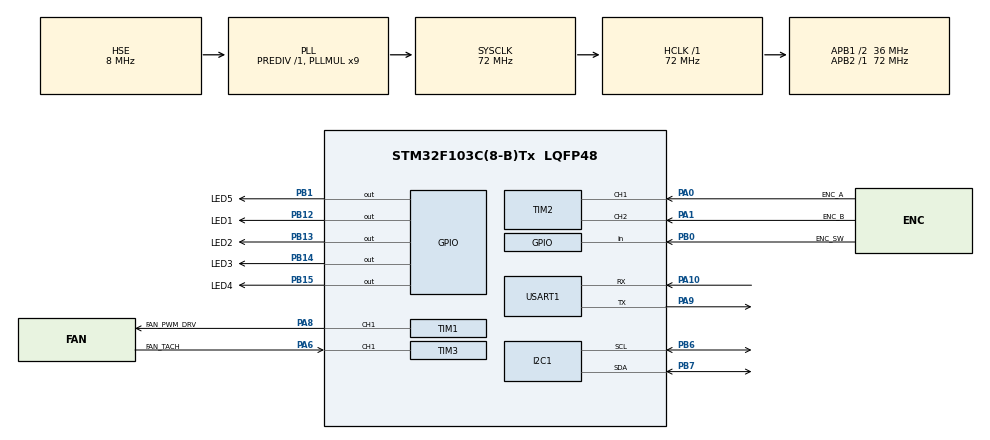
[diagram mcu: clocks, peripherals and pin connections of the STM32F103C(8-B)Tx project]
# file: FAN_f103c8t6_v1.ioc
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FREERTOS.Tasks01=defaultTask,24,128,StartDefaultTask,Default,NULL,Dynamic,NULL,NULL;myTask02,11,256,StartTask02,Default,NULL,Dynamic,NULL,NULL;myTask03,11,256,StartTask03,Default,NULL,Dynamic,NULL,NULL
FREERTOS.configTOTAL_HEAP_SIZE=8192
Mcu.Family=STM32F1
Mcu.Name=STM32F103C(8-B)Tx
Mcu.Package=LQFP48
NVIC.I2C1_ER_IRQn=true\:5\:0\:false\:false\:true\:true\:true\:true\:true
NVIC.I2C1_EV_IRQn=true\:5\:0\:false\:false\:true\:true\:true\:true\:true
NVIC.PriorityGroup=NVIC_PRIORITYGROUP_4
NVIC.TIM2_IRQn=true\:5\:0\:false\:false\:true\:true\:true\:true\:true
NVIC.TIM3_IRQn=true\:5\:0\:false\:false\:true\:true\:true\:true\:true
NVIC.TIM4_IRQn=true\:15\:0\:false\:false\:true\:false\:false\:true\:true
NVIC.TimeBase=TIM4_IRQn
NVIC.TimeBaseIP=TIM4
NVIC.USART1_IRQn=true\:5\:0\:false\:false\:true\:true\:true\:true\:true
PA0-WKUP.GPIO_Label=ENC_A
PA0-WKUP.Signal=S_TIM2_CH1_ETR
PA1.GPIO_Label=ENC_B
PA1.Signal=S_TIM2_CH2
PA10.Mode=Asynchronous
PA10.Signal=USART1_RX
PA13.Mode=JTAG_5_pins
PA13.Signal=SYS_JTMS-SWDIO
PA14.Mode=JTAG_5_pins
PA14.Signal=SYS_JTCK-SWCLK
PA15.Mode=JTAG_5_pins
PA15.Signal=SYS_JTDI
PA6.GPIO_Label=FAN_TACH
PA6.Signal=S_TIM3_CH1
PA8.GPIO_Label=FAN_PWM_DRV
PA8.Signal=S_TIM1_CH1
PA9.Mode=Asynchronous
PA9.Signal=USART1_TX
PB0.GPIO_Label=ENC_SW
PB0.Signal=GPIO_Input
PB1.GPIO_Label=LED5
PB1.PinState=GPIO_PIN_SET
PB1.Signal=GPIO_Output
PB12.GPIO_Label=LED1
PB12.PinState=GPIO_PIN_SET
PB12.Signal=GPIO_Output
PB13.GPIO_Label=LED2
PB13.PinState=GPIO_PIN_SET
PB13.Signal=GPIO_Output
PB14.GPIO_Label=LED3
PB14.PinState=GPIO_PIN_SET
PB14.Signal=GPIO_Output
PB15.GPIO_Label=LED4
PB15.PinState=GPIO_PIN_SET
PB15.Signal=GPIO_Output
PB3.Mode=JTAG_5_pins
PB3.Signal=SYS_JTDO-TRACESWO
PB4.Mode=JTAG_5_pins
PB4.Signal=SYS_NJTRST
PB6.Mode=I2C
PB6.Signal=I2C1_SCL
PB7.Mode=I2C
PB7.Signal=I2C1_SDA
PD0-OSC_IN.Mode=HSE-External-Oscillator
PD0-OSC_IN.Signal=RCC_OSC_IN
PD1-OSC_OUT.Mode=HSE-External-Oscillator
PD1-OSC_OUT.Signal=RCC_OSC_OUT
ProjectManager.HeapSize=0x200
ProjectManager.StackSize=0x400
ProjectManager.TargetToolchain=MDK-ARM V5.32
RCC.AHBFreq_Value=72000000
RCC.APB1CLKDivider=RCC_HCLK_DIV2
RCC.APB1Freq_Value=36000000
RCC.APB1TimFreq_Value=72000000
RCC.APB2Freq_Value=72000000
RCC.APB2TimFreq_Value=72000000
RCC.HCLKFreq_Value=72000000
RCC.PLLMUL=RCC_PLL_MUL9
RCC.PLLSourceVirtual=RCC_PLLSOURCE_HSE
RCC.SYSCLKFreq_VALUE=72000000
RCC.SYSCLKSource=RCC_SYSCLKSOURCE_PLLCLK
RCC.USBFreq_Value=72000000
SH.S_TIM1_CH1.0=TIM1_CH1,PWM Generation1 CH1
SH.S_TIM2_CH1_ETR.0=TIM2_CH1,Encoder_Interface
SH.S_TIM2_CH2.0=TIM2_CH2,Encoder_Interface
SH.S_TIM3_CH1.0=TIM3_CH1,Input_Capture1_from_TI1
TIM1.Channel-PWM\ Generation1\ CH1=TIM_CHANNEL_1
TIM1.Period=2879
TIM2.EncoderMode=TIM_ENCODERMODE_TI12
TIM2.IC1Filter=15
TIM2.IC2Filter=15
TIM3.Channel-Input_Capture1_from_TI1=TIM_CHANNEL_1
TIM3.ICFilter_CH1=8
TIM3.ICPolarity_CH1=TIM_INPUTCHANNELPOLARITY_FALLING
TIM3.Period=65535
TIM3.Prescaler=7199
USART1.VirtualMode=VM_ASYNC
VP_FREERTOS_VS_CMSIS_V2.Mode=CMSIS_V2
VP_SYS_VS_tim4.Mode=TIM4
VP_TIM1_VS_ClockSourceINT.Mode=Internal
VP_TIM3_VS_ClockSourceINT.Mode=Internal
board=custom

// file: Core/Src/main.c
/* USER CODE BEGIN Header */
/**
  ******************************************************************************
  * @file           : main.c
  * @brief          : Main program body
  ******************************************************************************
  * @attention
  *
  * Copyright (c) 2026 STMicroelectronics.
  * All rights reserved.
  *
  * This software is licensed under terms that can be found in the LICENSE file
  * in the root directory of this software component.
  * If no LICENSE file comes with this software, it is provided AS-IS.
  *
  ******************************************************************************
  */
/* USER CODE END Header */
#include "main.h"
#include "cmsis_os.h"
#include "i2c.h"
#include "tim.h"
#include "usart.h"
#include "gpio.h"

void SystemClock_Config(void);
void MX_FREERTOS_Init(void);

int main(void)
{

  /* MCU Configuration--------------------------------------------------------*/

  /* Reset of all peripherals, Initializes the Flash interface and the Systick. */
  HAL_Init();

  /* Configure the system clock */
  SystemClock_Config();

  /* Initialize all configured peripherals */
  MX_GPIO_Init();
  MX_I2C1_Init();
  MX_TIM1_Init();
  MX_TIM2_Init();
  MX_TIM3_Init();
  MX_USART1_UART_Init();

  /* Init scheduler */
  osKernelInitialize();  /* Call init function for freertos objects (in cmsis_os2.c) */
  MX_FREERTOS_Init();

  /* Start scheduler */
  osKernelStart();

  /* We should never get here as control is now taken by the scheduler */

  /* Infinite loop */
  while (1)
  {

  }
}

void SystemClock_Config(void)
{
  RCC_OscInitTypeDef RCC_OscInitStruct = {0};
  RCC_ClkInitTypeDef RCC_ClkInitStruct = {0};

  /** Initializes the RCC Oscillators according to the specified parameters
  * in the RCC_OscInitTypeDef structure.
  */
  RCC_OscInitStruct.OscillatorType = RCC_OSCILLATORTYPE_HSE;
  RCC_OscInitStruct.HSEState = RCC_HSE_ON;
  RCC_OscInitStruct.HSEPredivValue = RCC_HSE_PREDIV_DIV1;
  RCC_OscInitStruct.HSIState = RCC_HSI_ON;
  RCC_OscInitStruct.PLL.PLLState = RCC_PLL_ON;
  RCC_OscInitStruct.PLL.PLLSource = RCC_PLLSOURCE_HSE;
  RCC_OscInitStruct.PLL.PLLMUL = RCC_PLL_MUL9;
  if (HAL_RCC_OscConfig(&RCC_OscInitStruct) != HAL_OK)
  {
    Error_Handler();
  }

  /** Initializes the CPU, AHB and APB buses clocks
  */
  RCC_ClkInitStruct.ClockType = RCC_CLOCKTYPE_HCLK|RCC_CLOCKTYPE_SYSCLK
                              |RCC_CLOCKTYPE_PCLK1|RCC_CLOCKTYPE_PCLK2;
  RCC_ClkInitStruct.SYSCLKSource = RCC_SYSCLKSOURCE_PLLCLK;
  RCC_ClkInitStruct.AHBCLKDivider = RCC_SYSCLK_DIV1;
  RCC_ClkInitStruct.APB1CLKDivider = RCC_HCLK_DIV2;
  RCC_ClkInitStruct.APB2CLKDivider = RCC_HCLK_DIV1;

  if (HAL_RCC_ClockConfig(&RCC_ClkInitStruct, FLASH_LATENCY_2) != HAL_OK)
  {
    Error_Handler();
  }
}

void HAL_TIM_PeriodElapsedCallback(TIM_HandleTypeDef *htim)
{
  if (htim->Instance == TIM4)
  {
    HAL_IncTick();
  }
}

void Error_Handler(void)
{
  __disable_irq();
  while (1)
  {
  }
}

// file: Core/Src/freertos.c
/* USER CODE BEGIN Header */
/**
  ******************************************************************************
  * File Name          : freertos.c
  * Description        : Code for freertos applications
  ******************************************************************************
  * @attention
  *
  * Copyright (c) 2026 STMicroelectronics.
  * All rights reserved.
  *
  * This software is licensed under terms that can be found in the LICENSE file
  * in the root directory of this software component.
  * If no LICENSE file comes with this software, it is provided AS-IS.
  *
  ******************************************************************************
  */
/* USER CODE END Header */

#include "FreeRTOS.h"
#include "task.h"
#include "main.h"
#include "cmsis_os.h"

/* USER CODE BEGIN Includes */

/* 引入用户自有的 Task1、Task2、Task3 业务入口声明。 */
#include "user_work.h"

/* USER CODE END Includes */

/* Definitions for defaultTask */
osThreadId_t defaultTaskHandle;
const osThreadAttr_t defaultTask_attributes = {
  .name = "defaultTask",
  .stack_size = 128 * 4,
  .priority = (osPriority_t) osPriorityNormal,
};
/* Definitions for myTask02 */
osThreadId_t myTask02Handle;
const osThreadAttr_t myTask02_attributes = {
  .name = "myTask02",
  .stack_size = 256 * 4,
  .priority = (osPriority_t) osPriorityLow3,
};
/* Definitions for myTask03 */
osThreadId_t myTask03Handle;
const osThreadAttr_t myTask03_attributes = {
  .name = "myTask03",
  .stack_size = 256 * 4,
  .priority = (osPriority_t) osPriorityLow3,
};

void StartDefaultTask(void *argument);
void StartTask02(void *argument);
void StartTask03(void *argument);

void MX_FREERTOS_Init(void); /* (MISRA C 2004 rule 8.1) */

void MX_FREERTOS_Init(void) {

  /* Create the thread(s) */
  /* creation of defaultTask */
  defaultTaskHandle = osThreadNew(StartDefaultTask, NULL, &defaultTask_attributes);

  /* creation of myTask02 */
  myTask02Handle = osThreadNew(StartTask02, NULL, &myTask02_attributes);

  /* creation of myTask03 */
  myTask03Handle = osThreadNew(StartTask03, NULL, &myTask03_attributes);

}

void StartDefaultTask(void *argument)
{
  /* USER CODE BEGIN StartDefaultTask */
  /* 保留 CubeMX 任务入口；Task1 的业务循环和等待由自有模块管理。 */
  for(;;)
  {
    /* 调用用户封装的 Task1 常驻任务，后续业务在 user_work.c 中维护。 */
    My_Task1();
  }
  /* USER CODE END StartDefaultTask */
}

void StartTask02(void *argument)
{
  /* USER CODE BEGIN StartTask02 */
  /* 保留 CubeMX 任务入口；Task2 的业务循环和等待由自有模块管理。 */
  for(;;)
  {
    /* 调用用户封装的 Task2 常驻任务，后续业务在 user_work.c 中维护。 */
    My_Task2();
  }
  /* USER CODE END StartTask02 */
}

void StartTask03(void *argument)
{
  /* USER CODE BEGIN StartTask03 */
  /* 保留 CubeMX 任务入口；Task3 的业务循环和等待由自有模块管理。 */
  for(;;)
  {
    /* 调用用户封装的 Task3 常驻任务，后续业务在 user_work.c 中维护。 */
    My_Task3();
  }
  /* USER CODE END StartTask03 */
}
